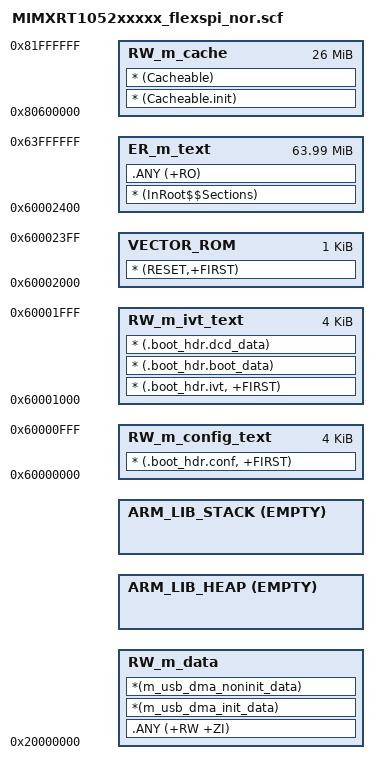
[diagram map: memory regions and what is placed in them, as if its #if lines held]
#! armcc -E
/*
** ###################################################################
**     Processors:          MIMXRT1052CVL5B
**                          MIMXRT1052DVL6B
**
**     Compiler:            Keil ARM C/C++ Compiler
**     Reference manual:    IMXRT1050RM Rev.1, 03/2018
**     Version:             rev. 0.1, 2017-01-10
**     Build:               b180131
**
**     Abstract:
**         Linker file for the Keil ARM C/C++ Compiler
**
**     The Clear BSD License
**     Copyright 2016 Freescale Semiconductor, Inc.
**     Copyright 2016-2018 NXP
**     All rights reserved.
**
**     Redistribution and use in source and binary forms, with or without
**     modification, are permitted (subject to the limitations in the
**     disclaimer below) provided that the following conditions are met:
**
**     * Redistributions of source code must retain the above copyright
**       notice, this list of conditions and the following disclaimer.
**
**     * Redistributions in binary form must reproduce the above copyright
**       notice, this list of conditions and the following disclaimer in the
**       documentation and/or other materials provided with the distribution.
**
**     * Neither the name of the copyright holder nor the names of its
**       contributors may be used to endorse or promote products derived from
**       this software without specific prior written permission.
**
**     NO EXPRESS OR IMPLIED LICENSES TO ANY PARTY'S PATENT RIGHTS ARE
**     GRANTED BY THIS LICENSE. THIS SOFTWARE IS PROVIDED BY THE COPYRIGHT
**     HOLDERS AND CONTRIBUTORS "AS IS" AND ANY EXPRESS OR IMPLIED
**     WARRANTIES, INCLUDING, BUT NOT LIMITED TO, THE IMPLIED WARRANTIES OF
**     MERCHANTABILITY AND FITNESS FOR A PARTICULAR PURPOSE ARE
**     DISCLAIMED. IN NO EVENT SHALL THE COPYRIGHT HOLDER OR CONTRIBUTORS BE
**     LIABLE FOR ANY DIRECT, INDIRECT, INCIDENTAL, SPECIAL, EXEMPLARY, OR
**     CONSEQUENTIAL DAMAGES (INCLUDING, BUT NOT LIMITED TO, PROCUREMENT OF
**     SUBSTITUTE GOODS OR SERVICES; LOSS OF USE, DATA, OR PROFITS; OR
**     BUSINESS INTERRUPTION) HOWEVER CAUSED AND ON ANY THEORY OF LIABILITY,
**     WHETHER IN CONTRACT, STRICT LIABILITY, OR TORT (INCLUDING NEGLIGENCE
**     OR OTHERWISE) ARISING IN ANY WAY OUT OF THE USE OF THIS SOFTWARE, EVEN
**     IF ADVISED OF THE POSSIBILITY OF SUCH DAMAGE.
**
**     http:                 www.nxp.com
**     mail:                 support@nxp.com
**
** ###################################################################
*/
 
; 外部QSPI FLASH 起始地址：0x60000000 --keep=*(.boot_hdr.ivt)
; 存放QSPI FLASH 参数，如几线制的 SPI Flash， SPI 的时钟频率， LUT 查找表， DDR/SDR 模式以及片选 CS管脚的 hold/setup time 等信息
; 0x00001000 = 4KB

#define m_flash_config_start           0x60000000 //m_flash_config域起始地址,定义在SPI FLASH里面(16MB)
#define m_flash_config_size            0x00001000	//m_flash_config域大小

; 存放Image Vector Table(IVT)
#define m_ivt_start                    0x60001000	//m_ivt域起始地址,定义在SPI FLASH里面(16MB)
#define m_ivt_size                     0x00001000	//m_ivt域大小

; 存放中断向量表
#define m_interrupts_start             0x60002000	//m_interrupts域起始地址,定义在SPI FLASH里面(16MB)
#define m_interrupts_size              0x00000400	//m_interrupts域大小

; 程序从这里开始存储
#define m_text_start                   0x60002400	//m_text域起始地址,定义在SPI FLASH里面(16MB)
#define m_text_size                    0x03FFDC00 //m_text域大小

; ITCM ：起始地址：0000_0000  ，大小128KB
; DTCM ：起始地址：2000_0000  ，大小128KB
; OCRAM：起始地址：2020_0000  ，大小256KB

; 片上储存 RAM(ITCM)  128KB  600M 访问
;#define m_data_start                   0x00000000
;#define m_data_size                    0x00020000

; 片上储存 RAM(DTCM)  128KB  600M 访问
#define m_data_start                   0x20000000			//m_data域起始地址,定义在DTRAM里面(256KB)
#define m_data_size                    0x00020000			//m_data域大小

#define m_cache_start                  0x80600000			//m_cache域起始地址,定义在SDRAM里面(6M开始,总共28MB),必须初始化SDRAM,才能使用此域
#define m_cache_size                   0x01A00000			//m_cache域大小

;#define m_ncache_start                 0x81A00000			//m_ncache域起始地址,定义在SDRAM里面(25M开始,总共6MB),必须初始化SDRAM,才能使用此域
;#define m_ncache_size                  0x00600000			//m_ncache域大小

; OCRAM，256KB  【 未用  1/4 主频运行 】
#define m_data2_start                  0x20200000	//m_data2域起始地址,定义在OCRAM里面(256KB)
#define m_data2_size                   0x00040000	//m_data2域大小

/* Sizes */
#if (defined(__stack_size__))
  #define Stack_Size                   __stack_size__
#else
  #define Stack_Size                   0x1000	//设置堆栈大小,一般设置大一点.
#endif

#if (defined(__heap_size__))
  #define Heap_Size                    __heap_size__
#else
  #define Heap_Size                    0x1000	//没用到系统自带的内存管理,则可以设置这里为0.
#endif

LR_m_rom_config m_flash_config_start m_flash_config_size {      //LR_m_rom_config加载域
	RW_m_config_text m_flash_config_start m_flash_config_size { //RW_m_config_text运行域,起始地址为:m_flash_config_start,大小为:m_flash_config_size
	* (.boot_hdr.conf, +FIRST)									//优先(+FIRST)将.boot_hdr.conf段放在这个域,需要定义.boot_hdr.conf段才有用.
	}
}

LR_m_rom_ivt m_ivt_start m_ivt_size {       //LR_m_rom_ivt加载域
	RW_m_ivt_text m_ivt_start m_ivt_size {  //RW_m_ivt_text运行域,起始地址为:m_ivt_start,大小为:m_ivt_size
	* (.boot_hdr.ivt, +FIRST)				//优先(+FIRST)将.boot_hdr.ivt段放在这个域,需要定义.boot_hdr.ivt段才有用.
	* (.boot_hdr.boot_data)					//将.boot_hdr.boot_data段放在这个域,需要定义.boot_hdr.boot_data段才有用.
	* (.boot_hdr.dcd_data)					//将.boot_hdr.dcd_data段放在这个域,需要定义.boot_hdr.dcd_data段才有用.
	}
}

LR_m_text m_interrupts_start m_text_start+m_text_size-m_interrupts_size {   ; load region size_region

  VECTOR_ROM m_interrupts_start m_interrupts_size { 		 //LR_m_interrupts加载域
    * (RESET,+FIRST)							    		 //优先(+FIRST)将RESET(中断向量表)段放这个域,实际上就是把中断向量表拷贝到m_interrupts_start
  }												   			 //RESET是一个段名,表示中断向量表(在.s文件定义);+FIRST表示时第一个要加载的.
  
  ER_m_text m_text_start m_text_size { 						 //ER_m_text运行域,起始地址为:m_text_start,大小为:m_text_size 
    * (InRoot$$Sections)			   						 //将所有的库段(C/C++标准库)放在root region.如__main.o,__scatter*.o等
    .ANY (+RO)						   						 //将只读数据(+RO)放这个域,任意分配.相当于程序就是存放在这个域的.
  }
  
  RW_m_data m_data_start m_data_size-Stack_Size-Heap_Size {  //RW_m_data运行域,起始地址为:m_data_start,大小为:m_data_size-Stack_Size-Heap_Size
    .ANY (+RW +ZI)											 //将RW和ZI数据(+RW +ZI)放这个域,任意分配.相当于内存数据就是存放在这个域的.
    *(m_usb_dma_init_data)									 //将m_usb_dma_init_data段数据全部放这个域,需要定义m_usb_dma_init_data段才有用.
    *(m_usb_dma_noninit_data)								 //将m_usb_dma_noninit_data段数据全部放这个域,需要定义m_usb_dma_noninit_data段才有用.
  }
  
  ARM_LIB_HEAP +0 EMPTY Heap_Size {   						 //ARM_LIB_HEAP运行域,起始地址紧挨RW_m_data域的末尾(+0),大小为:Heap_Size,即定义堆区(heap).
  }									  						 //EMPTY的意思位保留空白内存块,一般给栈/堆使用.
  
  ARM_LIB_STACK m_data_start+m_data_size EMPTY -Stack_Size { //ARM_LIB_STACK运行域,起始地址为:m_data_start+m_data_size-Stack_Size,大小为:Stack_Size
  }														     //-Stack_Size表示从起始地址位置,往前偏移Stack_Size,得到真正的起始地址,结束地址为起始地址的设置.
  
;  RW_m_ncache m_ncache_start m_ncache_size {				 //RW_m_ncache运行域,起始地址为:m_ncache_start,大小为:m_ncache_size.
;    * (NonCacheable.init)					 				 //将NonCacheable.init段数据全部放这个域,需要定义NonCacheable.init段才有用.
;    * (NonCacheable)						 				 //将NonCacheable段数据全部放这个域,需要定义NonCacheable段才有用.
;  }
  
  RW_m_cache m_cache_start m_cache_size { 					 //RW_m_cache运行域,起始地址为:m_cache_start,大小为:m_cache_size.
    * (Cacheable.init)										 //将Cacheable.init段数据全部放这个域,需要定义Cacheable.init段才有用.
    * (Cacheable)											 //将Cacheable段数据全部放这个域,需要定义Cacheable段才有用.
  }
  
}
